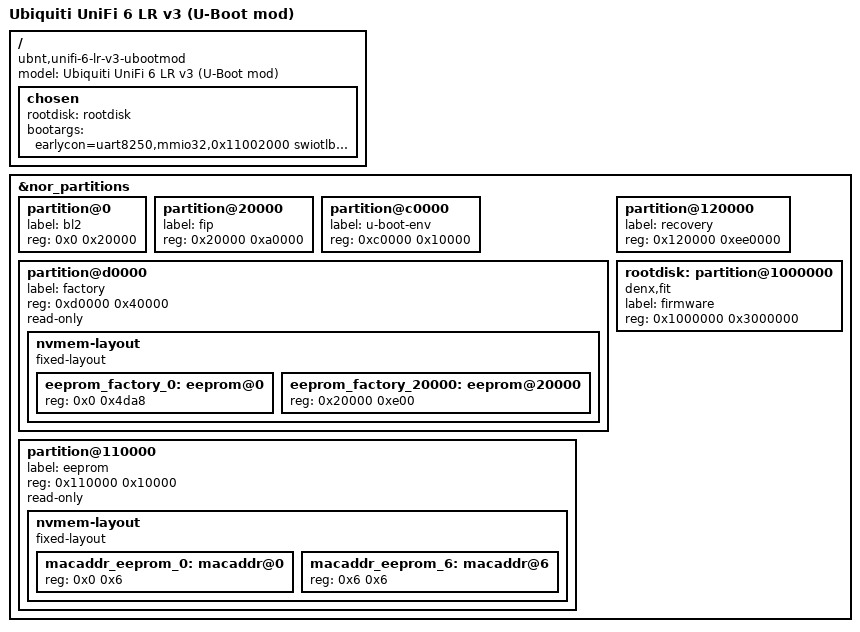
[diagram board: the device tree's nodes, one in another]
// SPDX-License-Identifier: GPL-2.0-or-later OR MIT

#include "mt7622-ubnt-unifi-6-lr-v3.dtsi"

/ {
	model = "Ubiquiti UniFi 6 LR v3 (U-Boot mod)";
	compatible = "ubnt,unifi-6-lr-v3-ubootmod", "mediatek,mt7622";

	chosen {
		rootdisk = <&rootdisk>;
		bootargs = "earlycon=uart8250,mmio32,0x11002000 swiotlb=512 console=ttyS0,115200n8 root=/dev/fit0 rootwait";
	};
};

&nor_partitions {
	partition@0 {
		label = "bl2";
		reg = <0x0 0x20000>;
	};

	partition@20000 {
		label = "fip";
		reg = <0x20000 0xa0000>;
	};

	partition@c0000 {
		label = "u-boot-env";
		reg = <0xc0000 0x10000>;
	};

	partition@d0000 {
		label = "factory";
		reg = <0xd0000 0x40000>;
		read-only;

		nvmem-layout {
			compatible = "fixed-layout";
			#address-cells = <1>;
			#size-cells = <1>;

			eeprom_factory_0: eeprom@0 {
				reg = <0x0 0x4da8>; /* actual length 0x400 */
			};

			eeprom_factory_20000: eeprom@20000 {
				reg = <0x20000 0xe00>;
			};
		};
	};

	partition@110000 {
		label = "eeprom";
		reg = <0x110000 0x10000>;
		read-only;

		nvmem-layout {
			compatible = "fixed-layout";
			#address-cells = <1>;
			#size-cells = <1>;

			macaddr_eeprom_0: macaddr@0 {
				reg = <0x0 0x6>;
			};

			macaddr_eeprom_6: macaddr@6 {
				reg = <0x6 0x6>;
			};
		};
	};

	partition@120000 {
		label = "recovery";
		reg = <0x120000 0xee0000>;
	};

	rootdisk: partition@1000000 {
		compatible = "denx,fit";
		label = "firmware";
		reg = <0x1000000 0x3000000>;
	};
};
